AUTOSAR XML (schema 4-2-2)
package /Components
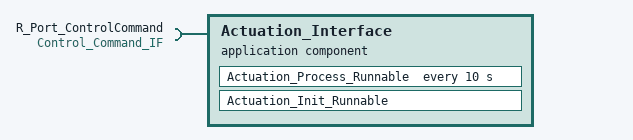
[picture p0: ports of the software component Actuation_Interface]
  application sw component type Actuation_Interface
    require port R_Port_ControlCommand: required-interface=Control_Command_IF
    behavior Actuation_Interface_InternalBehavior
      init event Actuation_Init_Event: start-on-event=Actuation_Init_Runnable
      timing event Actuation_Process_Event: start-on-event=Actuation_Process_Runnable, period=10
      runnable Actuation_Init_Runnable: symbol=Actuation_Init
        parameter access PA_Init_Longitudinal_Params: accessed-parameter=R_Port_ControlCommand.Longitudinal_Command
        parameter access PA_Init_Lateral_Params: accessed-parameter=R_Port_ControlCommand.Lateral_Command
      runnable Actuation_Process_Runnable: minimum-start-interval=10, symbol=Actuation_Process
        data-receive-point-by-arguments:
          access VA_Recv_Longitudinal_Command: accessed-variable=R_Port_ControlCommand.Longitudinal_Command
          access VA_Recv_Lateral_Command: accessed-variable=R_Port_ControlCommand.Lateral_Command
        parameter access PA_Run_Longitudinal_Params: accessed-parameter=R_Port_ControlCommand.Longitudinal_Command
        parameter access PA_Run_Lateral_Params: accessed-parameter=R_Port_ControlCommand.Lateral_Command
